VERSION ""

NS_ :

BS_:

BU_: SS EV ACU PT Gateway
VAL_TABLE_ ACS1_DrivingStateMachine 7 "ERROR" 6 "EMERGENCY" 5 "INTERVENTION" 4 "IPC" 3 "REMOTE" 2 "MANUAL" 1 "CHECK" 0 "IDLE" ;
VAL_TABLE_ gear 1 "Request" 0 "No Request" ;

BO_ 3221225472 VECTOR__INDEPENDENT_SIG_MSG: 0 Vector__XXX
 SG_ EPB1_Checksum_Copy_4 : 0|8@1+ (1,0) [0|0] "" Vector__XXX
 SG_ ACS3_Data7 : 0|8@1+ (1,0) [0|255] "" Vector__XXX
 SG_ ACS3_Data6 : 0|8@1+ (1,0) [0|255] "" Vector__XXX
 SG_ ACS3_Data5 : 0|8@1+ (1,0) [0|255] "" Vector__XXX
 SG_ ACS3_Data4 : 0|8@1+ (1,0) [0|255] "" Vector__XXX
 SG_ ACS3_Data3 : 0|8@1+ (1,0) [0|255] "" Vector__XXX
 SG_ ACS3_Data2 : 0|8@1+ (1,0) [0|255] "" Vector__XXX
 SG_ ACS3_Data1 : 0|8@1+ (1,0) [0|255] "" Vector__XXX
 SG_ ACS3_Data0 : 0|8@1+ (1,0) [0|255] "" Vector__XXX
 SG_ DCDC1_Temperature : 0|8@1+ (1,-40) [-40|210] "¡æ" Vector__XXX
 SG_ DCDC1_Status : 0|2@1+ (1,0) [0|3] "" Vector__XXX
 SG_ DCDC1_OutputVoltage : 0|8@1+ (0.1,0) [0|25] "V" Vector__XXX
 SG_ DCDC1_OutputCurrent : 0|10@1+ (1,0) [0|1000] "A" Vector__XXX
 SG_ DCDC1_LiveCounter : 0|4@1+ (1,0) [0|15] "count" Vector__XXX
 SG_ DCDC1_InputVoltage : 0|10@1+ (1,0) [0|1000] "V" Vector__XXX
 SG_ DCDC1_InputCurrent : 0|8@1+ (0.1,0) [0|25] "A" Vector__XXX
 SG_ DCDC1_Checksum : 0|8@1+ (1,0) [0|255] "check" Vector__XXX
 SG_ MCU1_TMTorque : 0|12@1+ (0.25,-500) [-500|500] "Nm" Vector__XXX
 SG_ MCU1_TMTemperature : 0|8@1+ (1,-40) [-40|210] "¡ãC" Vector__XXX
 SG_ MCU1_TMSpeed : 0|16@1+ (1,-30000) [-30000|30000] "rpm" Vector__XXX
 SG_ MCU1_TMCapacitanceVoltage : 0|9@1+ (1,0) [0|500] "V" Vector__XXX
 SG_ MCU1_LiveCounter : 0|4@1+ (1,0) [0|15] "count" Vector__XXX
 SG_ MCU1_Checksum : 0|8@1+ (1,0) [0|255] "check" Vector__XXX
 SG_ ESC1_LiveCounter : 0|4@1+ (1,0) [0|15] "count" Vector__XXX
 SG_ ESC1_Checksum : 0|8@1+ (1,0) [0|255] "check" Vector__XXX
 SG_ ESC1_YawRate : 0|12@1+ (0.05,-100) [-100|100] "deg/s" Vector__XXX
 SG_ ESC1_AccelerationX : 0|12@1+ (0.01,-20) [-20|20] "m/s2" Vector__XXX
 SG_ ESC1_AccelerationY : 0|12@1+ (0.01,-20) [-20|20] "m/s2" Vector__XXX
 SG_ ENV1_LiveCounter : 0|4@1+ (1,0) [0|15] "count" Vector__XXX
 SG_ ENV1_Checksum : 0|8@1+ (1,0) [0|255] "check" Vector__XXX
 SG_ ENV1_TimeYear : 0|6@1+ (1,2000) [2000|2063] "Year" Vector__XXX
 SG_ ENV1_TimeSecond : 0|6@1+ (1,0) [0|59] "Second" Vector__XXX
 SG_ ENV1_TimeMonth : 0|4@1+ (1,1) [1|12] "Month" Vector__XXX
 SG_ ENV1_TimeMinute : 0|6@1+ (1,0) [0|59] "Minute" Vector__XXX
 SG_ ENV1_TimeHour : 0|5@1+ (1,0) [0|23] "Hour" Vector__XXX
 SG_ ENV1_TimeDay : 0|5@1+ (1,1) [1|31] "Day" Vector__XXX
 SG_ ENV1_RainIntensity : 0|4@1+ (10,0) [0|150] "%" Vector__XXX
 SG_ ENV1_BrightnessH : 0|10@1+ (6,0) [0|6138] "LUX" Vector__XXX
 SG_ EPS1_LKAStatus : 0|3@1+ (1,0) [0|7] "" Vector__XXX
 SG_ EPS1_ElectricLoad : 0|8@1+ (0.5,0) [0|120] "A" Vector__XXX
 SG_ EPS1_APAErrorStatus : 0|1@1+ (1,0) [0|1] "" Vector__XXX
 SG_ EPS1_APARequestFeedback : 0|1@1+ (1,0) [0|1] "" Vector__XXX
 SG_ EPS1_APAAbortFeedback : 0|5@1+ (1,0) [0|31] "" Vector__XXX
 SG_ EPS1_OverlayInputTorque : 0|11@1+ (0.01,-10) [-10|10] "Nm" Vector__XXX
 SG_ EPS1_LiveCounter : 0|4@1+ (1,0) [0|15] "count" Vector__XXX
 SG_ EPS1_HandSteeringTorque : 0|11@1+ (0.01,-10) [-10|10] "Nm" Vector__XXX
 SG_ EPS1_Checksum : 0|8@1+ (1,0) [0|255] "check" Vector__XXX
 SG_ BDRR_WinButtonRR_ST : 0|3@1+ (1,0) [0|0] "" Vector__XXX
 SG_ BDRL_WinButtonRL_ST : 0|3@1+ (1,0) [0|0] "" Vector__XXX
 SG_ BDFR_WinButtonFR_ST : 0|3@1+ (1,0) [0|0] "" Vector__XXX
 SG_ A_Test_Data : 0|32@1- (1,0) [0|0] "" Vector__XXX
 SG_ BDFL_MirRightButton_ST : 0|1@1+ (1,0) [0|0] "" Vector__XXX
 SG_ BDFL_MirLeftButton_ST : 0|1@1+ (1,0) [0|0] "" Vector__XXX
 SG_ BDFL_MirButtonUP_ST : 0|1@1+ (1,0) [0|0] "" Vector__XXX
 SG_ BDFL_MirButtonRight_ST : 0|1@1+ (1,0) [0|0] "" Vector__XXX
 SG_ BDFL_MirButtonLeft_ST : 0|1@1+ (1,0) [0|0] "" Vector__XXX
 SG_ BDFL_MirButtonDown_ST : 0|1@1+ (1,0) [0|0] "" Vector__XXX
 SG_ BDFL_UnLockButton_ST : 0|1@1+ (1,0) [0|0] "" Vector__XXX
 SG_ BDFL_LockButton_ST : 0|1@1+ (1,0) [0|0] "" Vector__XXX
 SG_ BDFL_BootButtonFL_ST : 0|1@1+ (1,0) [0|0] "" Vector__XXX
 SG_ BDFL_WinButtonRR_ST : 0|3@1+ (1,0) [0|0] "" Vector__XXX
 SG_ BDFL_WinButtonRL_ST : 0|3@1+ (1,0) [0|0] "" Vector__XXX
 SG_ BDFL_WinButtonFR_ST : 0|3@1+ (1,0) [0|0] "" Vector__XXX
 SG_ BDFL_WinButtonFL_ST : 0|3@1+ (1,0) [0|0] "" Vector__XXX

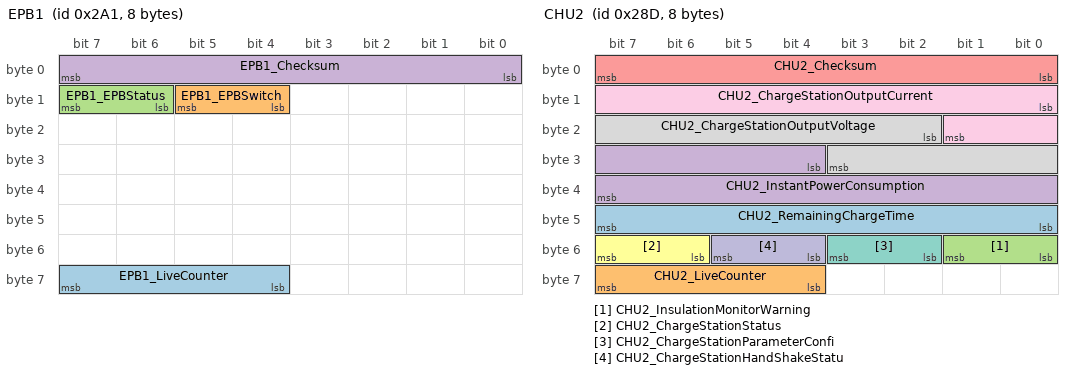
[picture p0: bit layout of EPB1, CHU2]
BO_ 673 EPB1: 8 Vector__XXX
 SG_ EPB1_LiveCounter : 60|4@1+ (1,0) [0|0] "" Vector__XXX
 SG_ EPB1_EPBSwitch : 12|2@1+ (1,0) [0|0] "" Vector__XXX
 SG_ EPB1_EPBStatus : 14|2@1+ (1,0) [0|0] "" Vector__XXX
 SG_ EPB1_Checksum : 0|8@1+ (1,0) [0|0] "" Vector__XXX

BO_ 512 BCM2: 8 Vector__XXX
 SG_ Key_Unlock : 1|1@1+ (1,0) [0|0] "" Vector__XXX
 SG_ Key_Lock : 0|1@1+ (1,0) [0|0] "" Vector__XXX

BO_ 530 VCU3: 8 PT
 SG_ VCU3_ThrottleVoltage : 32|11@1+ (1,0) [0|2000] "mV" Vector__XXX
 SG_ VCU3_MainSwitch : 22|1@1+ (1,0) [0|1] "" Vector__XXX
 SG_ VCU3_IncreaseSpeedSwitch : 26|1@1+ (1,0) [0|1] "" Vector__XXX
 SG_ VCU3_IncreaseDistanceSwitch : 24|1@1+ (1,0) [0|1] "" Vector__XXX
 SG_ VCU3_DecreaseSpeedSwitch : 27|1@1+ (1,0) [0|1] "" Vector__XXX
 SG_ VCU3_DecreaseDistanceSwitch : 25|1@1+ (1,0) [0|1] "" Vector__XXX
 SG_ VCU3_CancelSwitch : 23|1@1+ (1,0) [0|1] "" Vector__XXX
 SG_ VCU3_GearSecurityButton : 20|1@1+ (1,0) [0|1] "" Vector__XXX
 SG_ VCU3_GearParkButton : 21|1@1+ (1,0) [0|1] "" Vector__XXX
 SG_ VCU3_GearLeverPosition : 16|3@1+ (1,0) [0|7] "" Vector__XXX
 SG_ VCU3_EPBSwitch : 28|2@1+ (1,0) [0|3] "" Vector__XXX
 SG_ VCU3_VacuumPressure : 48|10@1+ (0.2,-108) [-108|96.6] "kPa" Vector__XXX
 SG_ VCU3_LiveCounter : 60|4@1+ (1,0) [0|15] "count" Vector__XXX
 SG_ VCU3_LeverInfo : 8|4@1+ (1,0) [0|15] "" Vector__XXX
 SG_ VCU3_EPBStatus : 30|2@1+ (1,0) [0|3] "" Vector__XXX
 SG_ VCU3_Checksum : 0|8@1+ (1,0) [0|255] "check" Vector__XXX
 SG_ VCU3_ActualGear : 12|4@1+ (1,0) [0|15] "" Vector__XXX

BO_ 653 CHU2: 8 EV
 SG_ CHU2_RemainingChargeTime : 40|8@1+ (5,0) [0|1000] "Min" Vector__XXX
 SG_ CHU2_LiveCounter : 60|4@1+ (1,0) [0|15] "count" Vector__XXX
 SG_ CHU2_InsulationMonitorWarning : 48|2@1+ (1,0) [0|3] "" Vector__XXX
 SG_ CHU2_InstantPowerConsumption : 28|12@1+ (0.5,-500) [-500|1500] "Kw" Vector__XXX
 SG_ CHU2_Checksum : 0|8@1+ (1,0) [0|255] "check" Vector__XXX
 SG_ CHU2_ChargeStationStatus : 54|2@1+ (1,0) [0|3] "" Vector__XXX
 SG_ CHU2_ChargeStationParameterConfi : 50|2@1+ (1,0) [0|3] "" Vector__XXX
 SG_ CHU2_ChargeStationOutputVoltage : 18|10@1+ (1,0) [0|1000] "V" Vector__XXX
 SG_ CHU2_ChargeStationOutputCurrent : 8|10@1+ (1,0) [0|1000] "A" Vector__XXX
 SG_ CHU2_ChargeStationHandShakeStatu : 52|2@1+ (1,0) [0|3] "" Vector__XXX

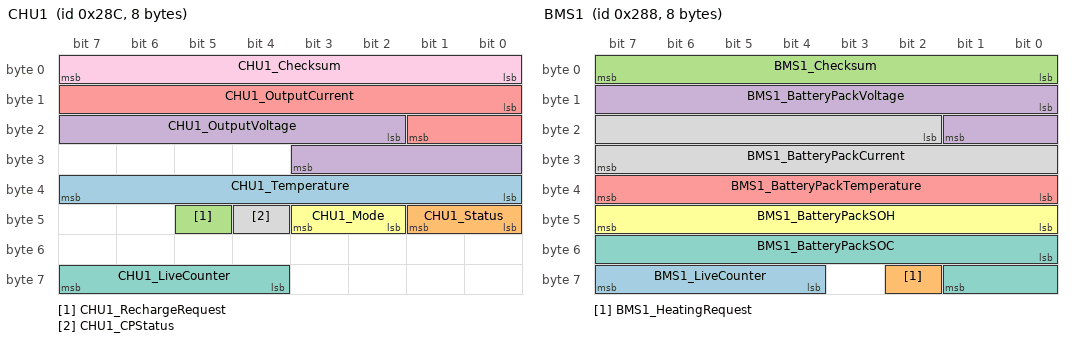
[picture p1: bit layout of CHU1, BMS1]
BO_ 652 CHU1: 8 EV
 SG_ CHU1_Temperature : 32|8@1+ (1,-40) [-40|210] "¡æ" Vector__XXX
 SG_ CHU1_Status : 40|2@1+ (1,0) [0|3] "" Vector__XXX
 SG_ CHU1_RechargeRequest : 45|1@1+ (1,0) [0|1] "" Vector__XXX
 SG_ CHU1_OutputVoltage : 18|10@1+ (1,0) [0|1000] "V" Vector__XXX
 SG_ CHU1_OutputCurrent : 8|10@1+ (0.1,0) [0|100] "A" Vector__XXX
 SG_ CHU1_Mode : 42|2@1+ (1,0) [0|3] "" Vector__XXX
 SG_ CHU1_LiveCounter : 60|4@1+ (1,0) [0|15] "count" Vector__XXX
 SG_ CHU1_CPStatus : 44|1@1+ (1,0) [0|1] "" Vector__XXX
 SG_ CHU1_Checksum : 0|8@1+ (1,0) [0|255] "check" Vector__XXX

BO_ 648 BMS1: 8 EV
 SG_ BMS1_LiveCounter : 60|4@1+ (1,0) [0|15] "count" Vector__XXX
 SG_ BMS1_HeatingRequest : 58|1@1+ (1,0) [0|1] "" Vector__XXX
 SG_ BMS1_Checksum : 0|8@1+ (1,0) [0|255] "check" Vector__XXX
 SG_ BMS1_BatteryPackVoltage : 8|10@1+ (1,0) [0|1000] "V" Vector__XXX
 SG_ BMS1_BatteryPackTemperature : 32|8@1+ (1,-40) [-40|210] "¡æ" Vector__XXX
 SG_ BMS1_BatteryPackSOH : 40|8@1+ (1,0) [0|100] "%" Vector__XXX
 SG_ BMS1_BatteryPackSOC : 48|10@1+ (0.1,0) [0|100] "%" Vector__XXX
 SG_ BMS1_BatteryPackCurrent : 18|14@1+ (0.1,-800) [-800|800] "A" Vector__XXX

BO_ 340 ACU4: 8 ACU
 SG_ ACU4_PowerRequest : 32|2@1+ (1,0) [0|3] "" Vector__XXX
 SG_ ACU4_RRWindow_Request : 30|2@1+ (1,0) [0|0] "" Vector__XXX
 SG_ ACU4_RLWindow_Request : 28|2@1+ (1,0) [0|0] "" Vector__XXX
 SG_ ACU4_Lock_Request : 16|2@1+ (1,0) [0|0] "" Vector__XXX
 SG_ ACU4_FRWindow_Request : 26|2@1+ (1,0) [0|0] "" Vector__XXX
 SG_ ACU4_FLWindow_Request : 24|2@1+ (1,0) [0|0] "" Vector__XXX
 SG_ ACU4_Boot_Request : 18|2@1+ (1,0) [0|0] "" Vector__XXX
 SG_ ACU4_RearWiperRequest : 22|2@1+ (1,0) [0|3] "" Vector__XXX
 SG_ ACU4_LED4Request : 59|1@1+ (1,0) [0|1] "" Vector__XXX
 SG_ ACU4_LED3Request : 58|1@1+ (1,0) [0|1] "" Vector__XXX
 SG_ ACU4_LED2Request : 57|1@1+ (1,0) [0|1] "" Vector__XXX
 SG_ ACU4_LED1Request : 56|1@1+ (1,0) [0|1] "" Vector__XXX
 SG_ ACU4_LampHorn : 11|1@1+ (1,0) [0|1] "" Vector__XXX
 SG_ ACU4_WhistleRequest : 14|2@1+ (1,0) [0|3] "" Vector__XXX
 SG_ ACU4_FrontWiperRequest : 20|2@1+ (1,0) [0|3] "" Vector__XXX
 SG_ ACU4_BeamLampRequest : 12|2@1+ (1,0) [0|3] "" Vector__XXX
 SG_ ACU4_LiveCounter : 60|4@1+ (1,0) [0|15] "count" Vector__XXX
 SG_ ACU4_Checksum : 0|8@1+ (1,0) [0|255] "check" Vector__XXX
 SG_ ACU4_SteeringLampRequest : 8|2@1+ (1,0) [0|3] "" Vector__XXX
 SG_ ACU4_HazardLampRequest : 10|1@1+ (1,0) [0|1] "" Vector__XXX

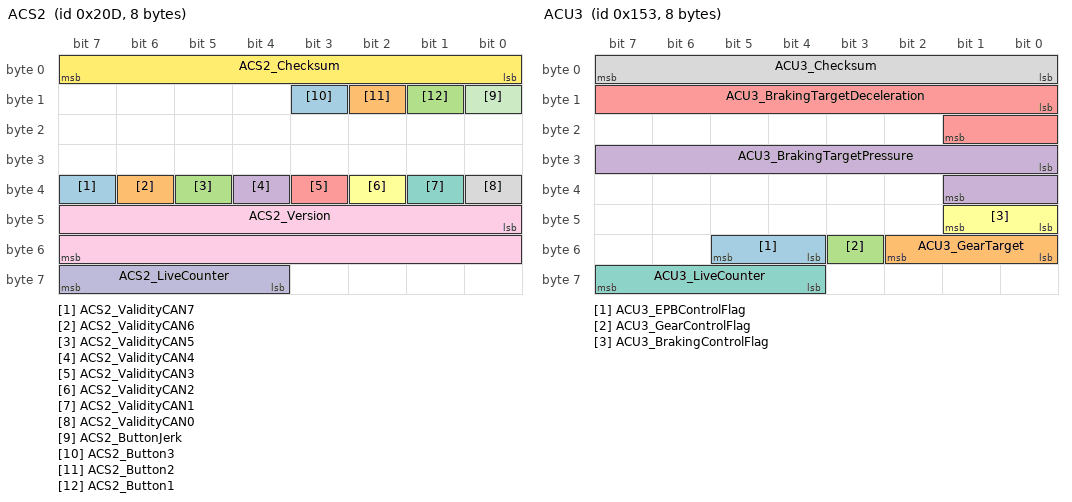
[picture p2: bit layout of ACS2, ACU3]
BO_ 525 ACS2: 8 PT
 SG_ ACS2_ValidityCAN7 : 39|1@1+ (1,0) [0|1] "" Vector__XXX
 SG_ ACS2_ValidityCAN6 : 38|1@1+ (1,0) [0|1] "" Vector__XXX
 SG_ ACS2_ValidityCAN5 : 37|1@1+ (1,0) [0|1] "" Vector__XXX
 SG_ ACS2_ValidityCAN4 : 36|1@1+ (1,0) [0|1] "" Vector__XXX
 SG_ ACS2_ValidityCAN3 : 35|1@1+ (1,0) [0|1] "" Vector__XXX
 SG_ ACS2_ValidityCAN2 : 34|1@1+ (1,0) [0|1] "" Vector__XXX
 SG_ ACS2_ValidityCAN1 : 33|1@1+ (1,0) [0|1] "" Vector__XXX
 SG_ ACS2_ValidityCAN0 : 32|1@1+ (1,0) [0|1] "" Vector__XXX
 SG_ ACS2_Version : 40|16@1+ (0.01,0) [0|655.35] "version" Vector__XXX
 SG_ ACS2_LiveCounter : 60|4@1+ (1,0) [0|15] "count" Vector__XXX
 SG_ ACS2_ButtonJerk : 8|1@1+ (1,0) [0|1] "" Vector__XXX
 SG_ ACS2_Checksum : 0|8@1+ (1,0) [0|255] "check" Vector__XXX
 SG_ ACS2_Button3 : 11|1@1+ (1,0) [0|1] "" Vector__XXX
 SG_ ACS2_Button2 : 10|1@1+ (1,0) [0|1] "" Vector__XXX
 SG_ ACS2_Button1 : 9|1@1+ (1,0) [0|1] "" Vector__XXX

BO_ 339 ACU3: 8 ACU
 SG_ ACU3_EPBControlFlag : 52|2@1+ (1,0) [0|3] "" Vector__XXX
 SG_ ACU3_GearTarget : 48|3@1+ (1,0) [0|7] "" Vector__XXX
 SG_ ACU3_GearControlFlag : 51|1@1+ (1,0) [0|1] "" Vector__XXX
 SG_ ACU3_BrakingTargetPressure : 24|10@1+ (0.01,0) [0|10] "Mpa" Vector__XXX
 SG_ ACU3_BrakingTargetDeceleration : 8|10@1+ (-0.01,0) [-10|0] "m/s2" Vector__XXX
 SG_ ACU3_BrakingControlFlag : 40|2@1+ (1,0) [0|3] "" Vector__XXX
 SG_ ACU3_LiveCounter : 60|4@1+ (1,0) [0|15] "count" Vector__XXX
 SG_ ACU3_Checksum : 0|8@1+ (1,0) [0|255] "check" Vector__XXX

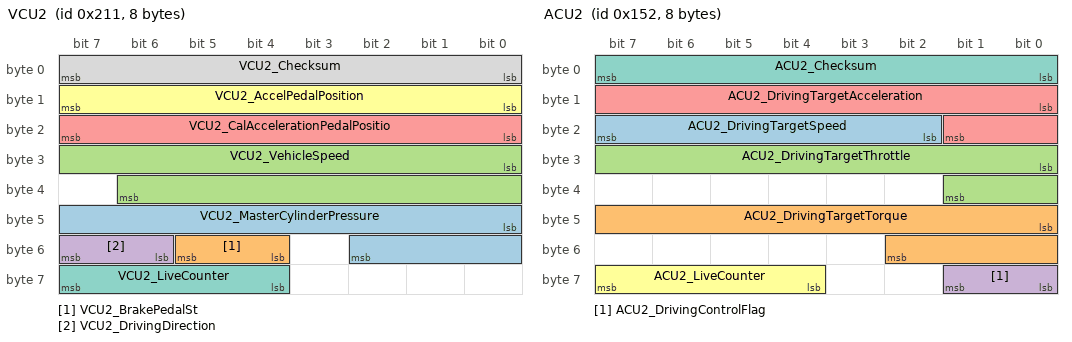
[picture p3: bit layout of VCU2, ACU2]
BO_ 529 VCU2: 8 PT
 SG_ VCU2_MasterCylinderPressure : 40|11@1+ (0.1,0) [0|200] "bar" Vector__XXX
 SG_ VCU2_BrakePedalSt : 52|2@1+ (1,0) [0|3] "" Vector__XXX
 SG_ VCU2_VehicleSpeed : 24|15@1+ (0.01,0) [0|300] "km/h" Vector__XXX
 SG_ VCU2_DrivingDirection : 54|2@1+ (1,0) [0|3] "" Vector__XXX
 SG_ VCU2_CalAccelerationPedalPositio : 16|8@1+ (0.4,0) [0|100] "%" Vector__XXX
 SG_ VCU2_AccelPedalPosition : 8|8@1+ (0.4,0) [0|100] "%" Vector__XXX
 SG_ VCU2_LiveCounter : 60|4@1+ (1,0) [0|15] "count" Vector__XXX
 SG_ VCU2_Checksum : 0|8@1+ (1,0) [0|255] "check" Vector__XXX

BO_ 338 ACU2: 8 ACU
 SG_ ACU2_DrivingTargetSpeed : 18|6@1+ (2,0) [0|126] "km/h" Vector__XXX
 SG_ ACU2_DrivingTargetTorque : 40|11@1+ (0.25,0) [0|350] "Nm" Vector__XXX
 SG_ ACU2_DrivingTargetThrottle : 24|10@1+ (0.1,0) [0|100] "%" Vector__XXX
 SG_ ACU2_DrivingControlFlag : 56|2@1+ (1,0) [0|3] "" Vector__XXX
 SG_ ACU2_DrivingTargetAcceleration : 8|10@1+ (0.01,0) [0|10] "m/s2" Vector__XXX
 SG_ ACU2_LiveCounter : 60|4@1+ (1,0) [0|15] "count" Vector__XXX
 SG_ ACU2_Checksum : 0|8@1+ (1,0) [0|255] "check" Vector__XXX

BO_ 524 ACS1: 8 PT
 SG_ ACS1_WorkMode : 48|2@1+ (1,0) [0|3] "" Vector__XXX
 SG_ ACS1_SteeringStateMachine : 12|4@1+ (1,0) [0|15] "value" Vector__XXX
 SG_ ACS1_GearStateMachine : 36|4@1+ (1,0) [0|15] "value" Vector__XXX
 SG_ ACS1_DrivingStateMachine : 20|4@1+ (1,0) [0|15] "value" Vector__XXX
 SG_ ACS1_BrakingStateMachine : 28|4@1+ (1,0) [0|15] "value" Vector__XXX
 SG_ ACS1_GearTakeOverSt : 34|2@1+ (1,0) [0|3] "" Vector__XXX
 SG_ ACS1_GearFailureSt : 46|2@1+ (1,0) [0|3] "" Vector__XXX
 SG_ ACS1_GearAutoControlSt : 32|2@1+ (1,0) [0|3] "" Vector__XXX
 SG_ ACS1_SteeringTakeOverSt : 10|2@1+ (1,0) [0|3] "" Vector__XXX
 SG_ ACS1_SteeringFailureSt : 40|2@1+ (1,0) [0|3] "" Vector__XXX
 SG_ ACS1_SteeringAutoControlSt : 8|2@1+ (1,0) [0|3] "" Vector__XXX
 SG_ ACS1_LiveCounter : 60|4@1+ (1,0) [0|15] "count" Vector__XXX
 SG_ ACS1_DrivingTakeOverSt : 18|2@1+ (1,0) [0|3] "" Vector__XXX
 SG_ ACS1_DrivingFailureSt : 42|2@1+ (1,0) [0|3] "" Vector__XXX
 SG_ ACS1_DrivingAutoControlSt : 16|2@1+ (1,0) [0|3] "" Vector__XXX
 SG_ ACS1_Checksum : 0|8@1+ (1,0) [0|255] "check" Vector__XXX
 SG_ ACS1_BrakingTakeOverSt : 26|2@1+ (1,0) [0|3] "" Vector__XXX
 SG_ ACS1_BrakingFailureSt : 44|2@1+ (1,0) [0|3] "" Vector__XXX
 SG_ ACS1_BrakingAutoControlSt : 24|2@1+ (1,0) [0|3] "" Vector__XXX

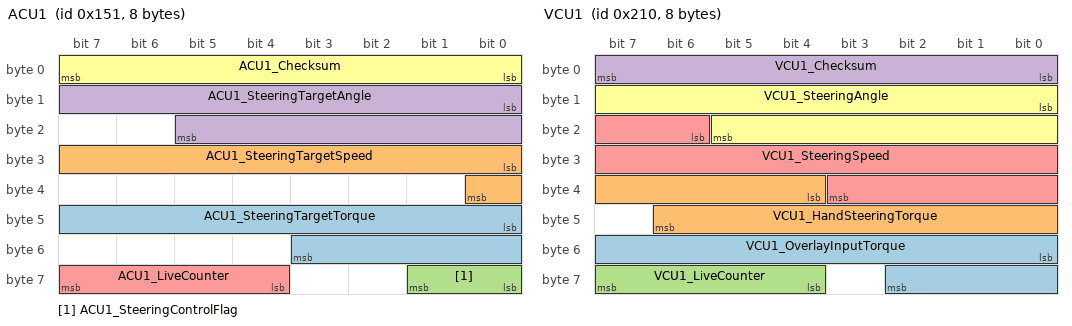
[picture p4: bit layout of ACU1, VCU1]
BO_ 337 ACU1: 8 ACU
 SG_ ACU1_SteeringTargetTorque : 40|12@1+ (0.01,-20) [-20|20] "Nm" Vector__XXX
 SG_ ACU1_SteeringTargetSpeed : 24|9@1+ (1,0) [0|500] "deg/s" Vector__XXX
 SG_ ACU1_SteeringControlFlag : 56|2@1+ (1,0) [0|3] "" Vector__XXX
 SG_ ACU1_SteeringTargetAngle : 8|14@1+ (0.1,-600) [-600|600] "deg" Vector__XXX
 SG_ ACU1_LiveCounter : 60|4@1+ (1,0) [0|15] "count" Vector__XXX
 SG_ ACU1_Checksum : 0|8@1+ (1,0) [0|255] "check" Vector__XXX

BO_ 528 VCU1: 8 PT
 SG_ VCU1_OverlayInputTorque : 48|11@1+ (0.01,-10) [-10|10] "Nm" Vector__XXX
 SG_ VCU1_HandSteeringTorque : 36|11@1+ (0.01,-10) [-10|10] "Nm" Vector__XXX
 SG_ VCU1_LiveCounter : 60|4@1+ (1,0) [0|15] "count" Vector__XXX
 SG_ VCU1_Checksum : 0|8@1+ (1,0) [0|255] "check" Vector__XXX
 SG_ VCU1_SteeringSpeed : 22|14@1+ (0.1,-600) [-600|600] "deg/s" Vector__XXX
 SG_ VCU1_SteeringAngle : 8|14@1+ (0.1,-600) [-600|600] "deg" Vector__XXX

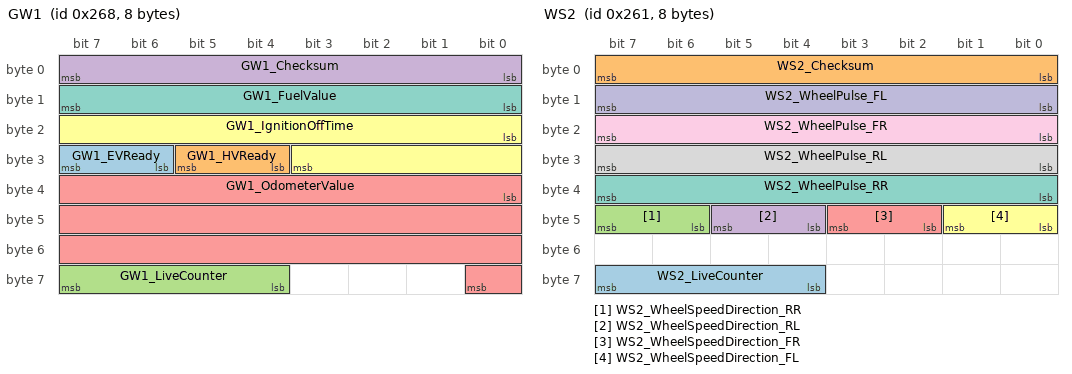
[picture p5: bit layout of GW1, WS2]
BO_ 616 GW1: 8 PT
 SG_ GW1_EVReady : 30|2@1+ (1,0) [0|3] "" Vector__XXX
 SG_ GW1_HVReady : 28|2@1+ (1,0) [0|3] "" Vector__XXX
 SG_ GW1_LiveCounter : 60|4@1+ (1,0) [0|15] "count" Vector__XXX
 SG_ GW1_Checksum : 0|8@1+ (1,0) [0|255] "check" Vector__XXX
 SG_ GW1_OdometerValue : 32|25@1+ (0.1,0) [0|3355443] "km" Vector__XXX
 SG_ GW1_IgnitionOffTime : 16|12@1+ (1,0) [0|4093] "minute" Vector__XXX
 SG_ GW1_FuelValue : 8|8@1+ (1,0) [0|254] "L" Vector__XXX

BO_ 609 WS2: 8 PT
 SG_ WS2_LiveCounter : 60|4@1+ (1,0) [0|15] "count" Vector__XXX
 SG_ WS2_Checksum : 0|8@1+ (1,0) [0|255] "check" Vector__XXX
 SG_ WS2_WheelSpeedDirection_RR : 46|2@1+ (1,0) [0|3] "" Vector__XXX
 SG_ WS2_WheelSpeedDirection_RL : 44|2@1+ (1,0) [0|3] "" Vector__XXX
 SG_ WS2_WheelSpeedDirection_FR : 42|2@1+ (1,0) [0|3] "" Vector__XXX
 SG_ WS2_WheelSpeedDirection_FL : 40|2@1+ (1,0) [0|3] "" Vector__XXX
 SG_ WS2_WheelPulse_RR : 32|8@1+ (1,0) [0|254] "pulse" Vector__XXX
 SG_ WS2_WheelPulse_RL : 24|8@1+ (1,0) [0|254] "pulse" Vector__XXX
 SG_ WS2_WheelPulse_FR : 16|8@1+ (1,0) [0|254] "pulse" Vector__XXX
 SG_ WS2_WheelPulse_FL : 8|8@1+ (1,0) [0|254] "pulse" Vector__XXX

BO_ 672 BCM1: 8 PT
 SG_ BCM1_PassengerSideBuckle : 54|2@1+ (1,0) [0|3] "" Vector__XXX
 SG_ BCM1_WiperSpeed : 37|3@1+ (1,0) [0|7] "" Vector__XXX
 SG_ BCM1_PositionLightSt : 32|2@1+ (1,0) [0|3] "" Vector__XXX
 SG_ BCM1_MirrorFoldSt_FR : 50|2@1+ (1,0) [0|3] "" Vector__XXX
 SG_ BCM1_MirrorFoldSt_FL : 48|2@1+ (1,0) [0|3] "" Vector__XXX
 SG_ BCM1_DriverSideBuckle : 52|2@1+ (1,0) [0|3] "" Vector__XXX
 SG_ BCM1_WiperStatus : 34|3@1+ (1,0) [0|7] "" Vector__XXX
 SG_ BCM1_LuggageDoorSt : 21|1@1+ (1,0) [0|1] "" Vector__XXX
 SG_ BCM1_LowBeamSt : 28|2@1+ (1,0) [0|3] "" Vector__XXX
 SG_ BCM1_HighBeamSt : 30|2@1+ (1,0) [0|3] "" Vector__XXX
 SG_ BCM1_EngHoodSt : 20|1@1+ (1,0) [0|1] "" Vector__XXX
 SG_ BCM1_RRDoorLockSt : 14|2@1+ (1,0) [0|3] "" Vector__XXX
 SG_ BCM1_RRDoorSt : 19|1@1+ (1,0) [0|1] "" Vector__XXX
 SG_ BCM1_RLDoorLockSt : 12|2@1+ (1,0) [0|3] "" Vector__XXX
 SG_ BCM1_RLDoorSt : 18|1@1+ (1,0) [0|1] "" Vector__XXX
 SG_ BCM1_PassengerDoorLockSt : 10|2@1+ (1,0) [0|3] "" Vector__XXX
 SG_ BCM1_PassengerDoorSt : 17|1@1+ (1,0) [0|1] "" Vector__XXX
 SG_ BCM1_DriverDoorLockSt : 8|2@1+ (1,0) [0|3] "" Vector__XXX
 SG_ BCM1_DriverDoorSt : 16|1@1+ (1,0) [0|1] "" Vector__XXX
 SG_ BCM1_LiveCounter : 60|4@1+ (1,0) [0|15] "count" Vector__XXX
 SG_ BCM1_Checksum : 0|8@1+ (1,0) [0|255] "check" Vector__XXX
 SG_ BCM1_SteeringLightSt : 24|2@1+ (1,0) [0|3] "" Vector__XXX
 SG_ BCM1_HazardLightSt : 26|2@1+ (1,0) [0|3] "" Vector__XXX

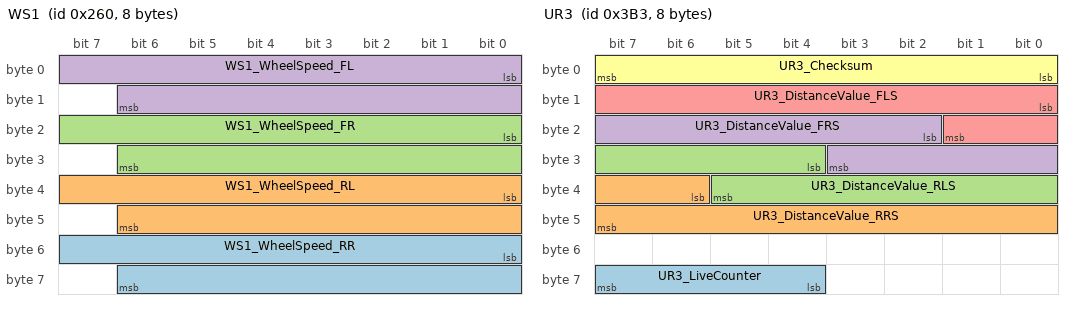
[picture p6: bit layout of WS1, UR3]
BO_ 608 WS1: 8 PT
 SG_ WS1_WheelSpeed_RR : 48|15@1+ (0.01,0) [0|300] "km/h" Vector__XXX
 SG_ WS1_WheelSpeed_RL : 32|15@1+ (0.01,0) [0|300] "km/h" Vector__XXX
 SG_ WS1_WheelSpeed_FR : 16|15@1+ (0.01,0) [0|300] "km/h" Vector__XXX
 SG_ WS1_WheelSpeed_FL : 0|15@1+ (0.01,0) [0|300] "km/h" Vector__XXX

BO_ 947 UR3: 8 SS
 SG_ UR3_LiveCounter : 60|4@1+ (1,0) [0|15] "count" Vector__XXX
 SG_ UR3_DistanceValue_RRS : 38|10@1+ (1,0) [0|1023] "cm" Vector__XXX
 SG_ UR3_DistanceValue_RLS : 28|10@1+ (1,0) [0|1023] "cm" Vector__XXX
 SG_ UR3_DistanceValue_FRS : 18|10@1+ (1,0) [0|1023] "cm" Vector__XXX
 SG_ UR3_DistanceValue_FLS : 8|10@1+ (1,0) [0|1023] "cm" Vector__XXX
 SG_ UR3_Checksum : 0|8@1+ (1,0) [0|255] "check" Vector__XXX

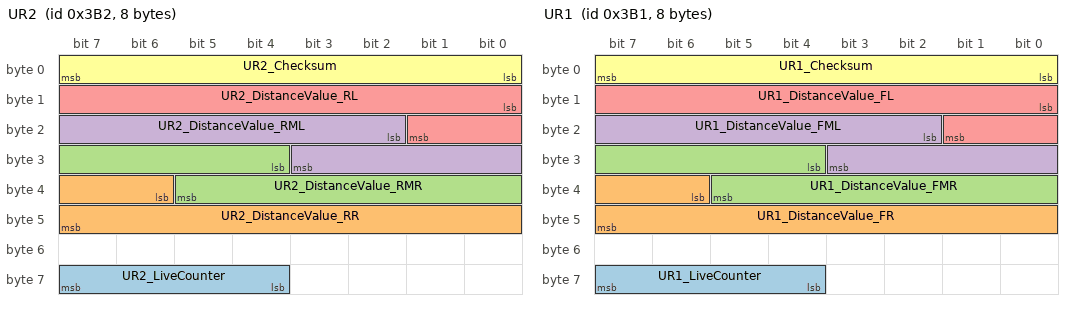
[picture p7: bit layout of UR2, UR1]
BO_ 946 UR2: 8 SS
 SG_ UR2_LiveCounter : 60|4@1+ (1,0) [0|15] "count" Vector__XXX
 SG_ UR2_DistanceValue_RR : 38|10@1+ (1,0) [0|1023] "cm" Vector__XXX
 SG_ UR2_DistanceValue_RMR : 28|10@1+ (1,0) [0|1023] "cm" Vector__XXX
 SG_ UR2_DistanceValue_RML : 18|10@1+ (1,0) [0|1023] "cm" Vector__XXX
 SG_ UR2_DistanceValue_RL : 8|10@1+ (1,0) [0|1023] "cm" Vector__XXX
 SG_ UR2_Checksum : 0|8@1+ (1,0) [0|255] "check" Vector__XXX

BO_ 945 UR1: 8 SS
 SG_ UR1_LiveCounter : 60|4@1+ (1,0) [0|15] "count" Vector__XXX
 SG_ UR1_DistanceValue_FR : 38|10@1+ (1,0) [0|1023] "cm" Vector__XXX
 SG_ UR1_DistanceValue_FMR : 28|10@1+ (1,0) [0|1023] "cm" Vector__XXX
 SG_ UR1_DistanceValue_FML : 18|10@1+ (1,0) [0|1023] "cm" Vector__XXX
 SG_ UR1_DistanceValue_FL : 8|10@1+ (1,0) [0|1023] "cm" Vector__XXX
 SG_ UR1_Checksum : 0|8@1+ (1,0) [0|255] "check" Vector__XXX

CM_ BO_ 3221225472 "This is a message for not used signals, created by Vector CANdb++ DBC OLE DB Provider.";
CM_ SG_ 3221225472 DCDC1_LiveCounter "The Livecounter is used to check the signal consistency of the messages";
CM_ SG_ 3221225472 DCDC1_Checksum "The checksum is used to check whether the data transmission errors";
CM_ SG_ 3221225472 MCU1_LiveCounter "The Livecounter is used to check the signal consistency of the messages";
CM_ SG_ 3221225472 MCU1_Checksum "The checksum is used to check whether the data transmission errors";
CM_ SG_ 3221225472 ESC1_LiveCounter "The Livecounter is used to check the signal consistency of the messages";
CM_ SG_ 3221225472 ESC1_Checksum "The checksum is used to check whether the data transmission errors";
CM_ SG_ 3221225472 ESC1_YawRate "This signal indicates the yaw rate data (real data; sign depends on mounting position).anticlockwise=positive, clockwise=negative";
CM_ SG_ 3221225472 ESC1_AccelerationX "The signal is LongitudinalAcceleration(exact value).Positive value represents  forward,  negative value represents backward.";
CM_ SG_ 3221225472 ESC1_AccelerationY "The signal is Lateral Acceleration(exact value).Positive value represents right side of vehicle, negative value represents  left side of vehicle.";
CM_ SG_ 3221225472 ENV1_LiveCounter "The Livecounter is used to check the signal consistency of the messages";
CM_ SG_ 3221225472 ENV1_Checksum "The checksum is used to check whether the data transmission errors";
CM_ SG_ 3221225472 ENV1_TimeYear "Indicates the GPS year";
CM_ SG_ 3221225472 ENV1_TimeSecond "Indicates the GPS second ";
CM_ SG_ 3221225472 ENV1_TimeMonth "Indicates the GPS month";
CM_ SG_ 3221225472 ENV1_TimeMinute "Indicates the GPS minute  ";
CM_ SG_ 3221225472 ENV1_TimeHour "Indicates the GPS hour";
CM_ SG_ 3221225472 ENV1_TimeDay "Indicates the GPS day";
CM_ SG_ 3221225472 ENV1_RainIntensity "This signal delivers information about rain intensity: from 0% (no rain) to 100% (very heavy rain).";
CM_ SG_ 3221225472 ENV1_BrightnessH "This signal  indicate the high precision light intensity expressed in 10 Bit.";
CM_ SG_ 3221225472 EPS1_LKAStatus "The signal indicates the status of LKA function";
CM_ SG_ 3221225472 EPS1_ElectricLoad "The signal indicates the load of the electric steering motor. If the load could not be measured or an error is detected on the motor, the invalid value of the signal is set";
CM_ SG_ 3221225472 EPS1_APAErrorStatus "The signal indicates the status of APA function error";
CM_ SG_ 3221225472 EPS1_APARequestFeedback "EPS APA Request Feedback";
CM_ SG_ 3221225472 EPS1_APAAbortFeedback "EPS APA Abort Feedback";
CM_ SG_ 3221225472 EPS1_OverlayInputTorque "The signal indicates the actual applied overlay toque in EPS.";
CM_ SG_ 3221225472 EPS1_LiveCounter "The Livecounter is used to check the signal consistency of the messages";
CM_ SG_ 3221225472 EPS1_HandSteeringTorque "The signal indicates the torque measured by the torque sensor at the steering wheel";
CM_ SG_ 3221225472 EPS1_Checksum "The checksum is used to check whether the data transmission errors";
CM_ SG_ 3221225472 BDRR_WinButtonRR_ST "1 down2 £» 2 down1£»3ÖÐ¼ä  £»4 up1   £»5up2";
CM_ SG_ 3221225472 BDRL_WinButtonRL_ST "1 down2 £» 2 down1£»3ÖÐ¼ä  £»4 up1   £»5up2";
CM_ SG_ 3221225472 BDFR_WinButtonFR_ST "1 down2 £» 2 down1£»3ÖÐ¼ä  £»4 up1   £»5up2";
CM_ SG_ 3221225472 BDFL_MirRightButton_ST "ºóÊÓ¾µÑ¡ÔñÓÒ°´¼ü£º1 °´ÏÂ £»0Ã»ÓÐ°´ÏÂ";
CM_ SG_ 3221225472 BDFL_MirLeftButton_ST "ºóÊÓ¾µÑ¡Ôñ×ó°´¼ü£º1 °´ÏÂ £»0Ã»ÓÐ°´ÏÂ";
CM_ SG_ 3221225472 BDFL_MirButtonUP_ST "ºóÊÓ¾µÏòÉÏµ÷Õû°´¼ü  1 °´ÏÂ£»0 Ã»ÓÐ°´ÏÂ
";
CM_ SG_ 3221225472 BDFL_MirButtonRight_ST "ºóÊÓ¾µÏòÓÒµ÷Õû°´¼ü  1 °´ÏÂ£»0 Ã»ÓÐ°´ÏÂ";
CM_ SG_ 3221225472 BDFL_MirButtonLeft_ST "ºóÊÓ¾µÏò×óµ÷Õû°´¼ü  1 °´ÏÂ£»0 Ã»ÓÐ°´ÏÂ";
CM_ SG_ 3221225472 BDFL_MirButtonDown_ST "ºóÊÓ¾µÏòÏÂµ÷Õû°´¼ü  1 °´ÏÂ£»0 Ã»ÓÐ°´ÏÂ";
CM_ SG_ 3221225472 BDFL_UnLockButton_ST "1,°´ÏÂ £»0£¬Ã»ÓÐ°´ÏÂ";
CM_ SG_ 3221225472 BDFL_LockButton_ST "1,°´ÏÂ £»0£¬Ã»ÓÐ°´ÏÂ";
CM_ SG_ 3221225472 BDFL_BootButtonFL_ST "1,°´ÏÂ 0£¬Ã»ÓÐ°´ÏÂ";
CM_ SG_ 3221225472 BDFL_WinButtonRR_ST "1 down2 £» 2 down1£»3ÖÐ¼ä  £»4 up1   £»5up2";
CM_ SG_ 3221225472 BDFL_WinButtonRL_ST "1 down2 £» 2 down1£»3ÖÐ¼ä  £»4 up1   £»5up2";
CM_ SG_ 3221225472 BDFL_WinButtonFR_ST "1 down2 £» 2 down1£»3ÖÐ¼ä  £»4 up1   £»5up2";
CM_ SG_ 3221225472 BDFL_WinButtonFL_ST "1 down2 £» 2 down1£»3ÖÐ¼ä  £»4 up1   £»5up2";
CM_ SG_ 673 EPB1_LiveCounter "The Livecounter is used to check the signal consistency of the messages";
CM_ SG_ 673 EPB1_EPBSwitch "0:no request 1: lock 2 :release 3: reserved";
CM_ SG_ 673 EPB1_EPBStatus "0: released 1: locked 2: releasing 3:locking";
CM_ SG_ 530 VCU3_MainSwitch "The signal indicates if the  ON/OFF cruise control switch is actived or not.";
CM_ SG_ 530 VCU3_IncreaseSpeedSwitch "The signal indicates if the increase speed switch is actived or not";
CM_ SG_ 530 VCU3_IncreaseDistanceSwitch "The signal indicates if  increase distance switch is actived or not";
CM_ SG_ 530 VCU3_DecreaseSpeedSwitch "The signal indicates if the decrease speed switch is actived or not.";
CM_ SG_ 530 VCU3_DecreaseDistanceSwitch "The signal indicates if decrease distance switch is actived or not";
CM_ SG_ 530 VCU3_CancelSwitch "The signal indicates if the cancel cruise control switch is actived or not";
CM_ SG_ 530 VCU3_GearSecurityButton "This signal indicate the security button in the knob is pressed or not.";
CM_ SG_ 530 VCU3_GearParkButton "This signal indicate the park button in the knob is pressed or not.";
CM_ SG_ 530 VCU3_GearLeverPosition "This signal indicate the current lever position.";
CM_ SG_ 530 VCU3_EPBSwitch "This signal indicate the EPB switch status.";
CM_ SG_ 530 VCU3_LiveCounter "The Livecounter is used to check the signal consistency of the messages";
CM_ SG_ 530 VCU3_LeverInfo "This signal indicates the lever position information which should be displayed on the dashboard. For H72G, only P,R,N,D,M,no connection.";
CM_ SG_ 530 VCU3_EPBStatus "The signal indicates the working status of EPB.";
CM_ SG_ 530 VCU3_Checksum "The checksum is used to check whether the data transmission errors";
CM_ SG_ 530 VCU3_ActualGear "The signal indicates to the actual gear status, it shows in which gear the transmission system is in at the moment (engaged gear).";
CM_ SG_ 653 CHU2_LiveCounter "The Livecounter is used to check the signal consistency of the messages";
CM_ SG_ 653 CHU2_Checksum "The checksum is used to check whether the data transmission errors";
CM_ SG_ 652 CHU1_LiveCounter "The Livecounter is used to check the signal consistency of the messages";
CM_ SG_ 652 CHU1_Checksum "The checksum is used to check whether the data transmission errors";
CM_ SG_ 648 BMS1_LiveCounter "The Livecounter is used to check the signal consistency of the messages";
CM_ SG_ 648 BMS1_Checksum "The checksum is used to check whether the data transmission errors";
CM_ SG_ 340 ACU4_PowerRequest "1: KL15 ON  3KL15 OFF";
CM_ SG_ 340 ACU4_RRWindow_Request "1:fall  2:rise 3:stop";
CM_ SG_ 340 ACU4_RLWindow_Request "1:fall  2:rise 3:stop";
CM_ SG_ 340 ACU4_Lock_Request "1:lock  2:unlock
";
CM_ SG_ 340 ACU4_FRWindow_Request "1:fall  2:rise 3:stop";
CM_ SG_ 340 ACU4_FLWindow_Request "1:fall  2:rise 3:stop";
CM_ SG_ 340 ACU4_Boot_Request "1:on  2:off 3:stop";
CM_ SG_ 340 ACU4_LampHorn "This signal is the the horn lamp or request";
CM_ SG_ 340 ACU4_WhistleRequest "0 stop 1 horn";
CM_ SG_ 340 ACU4_FrontWiperRequest "0 stop 1:inject water 2slow 3fast";
CM_ SG_ 340 ACU4_BeamLampRequest "0:OFF 1:LOW 2£ºHIGH";
CM_ SG_ 340 ACU4_LiveCounter "The Livecounter is used to check the signal consistency of the messages";
CM_ SG_ 340 ACU4_Checksum "The checksum is used to check whether the data transmission errors";
CM_ SG_ 340 ACU4_SteeringLampRequest "This signal is steering light request";
CM_ SG_ 340 ACU4_HazardLampRequest "This signal is hazard light request";
CM_ SG_ 525 ACS2_ValidityCAN7 "This signal indicates the validity of CAN5";
CM_ SG_ 525 ACS2_ValidityCAN6 "This signal indicates the validity of CAN4";
CM_ SG_ 525 ACS2_ValidityCAN5 "This signal indicates the validity of CAN5";
CM_ SG_ 525 ACS2_ValidityCAN4 "This signal indicates the validity of CAN4";
CM_ SG_ 525 ACS2_ValidityCAN3 "This signal indicates the validity of CAN3";
CM_ SG_ 525 ACS2_ValidityCAN2 "This signal indicates the validity of CAN2";
CM_ SG_ 525 ACS2_ValidityCAN1 "This signal indicates the validity of CAN1";
CM_ SG_ 525 ACS2_ValidityCAN0 "This signal indicates the validity of CAN0";
CM_ SG_ 525 ACS2_Version "This signal indicates the version of software";
CM_ SG_ 525 ACS2_LiveCounter "The Livecounter is used to check the signal consistency of the messages";
CM_ SG_ 525 ACS2_ButtonJerk "This signal indicates the state of Jerk Button";
CM_ SG_ 525 ACS2_Checksum "The checksum is used to check whether the data transmission errors";
CM_ SG_ 525 ACS2_Button3 "This signal indicates the state of Button2";
CM_ SG_ 525 ACS2_Button2 "This signal indicates the state of Button2";
CM_ SG_ 525 ACS2_Button1 "This signal indicates the state of Button1";
CM_ SG_ 339 ACU3_EPBControlFlag "This signal is the status of the braking control request";
CM_ SG_ 339 ACU3_GearTarget "This signal is gear request";
CM_ SG_ 339 ACU3_GearControlFlag "This signal is the status of the gear control request";
CM_ SG_ 339 ACU3_BrakingTargetPressure "This signal is deceleration request for wheel brake";
CM_ SG_ 339 ACU3_BrakingTargetDeceleration "This signal is deceleration request for wheel brake";
CM_ SG_ 339 ACU3_BrakingControlFlag "This signal is the status of the braking control request";
CM_ SG_ 339 ACU3_LiveCounter "The Livecounter is used to check the signal consistency of the messages";
CM_ SG_ 339 ACU3_Checksum "The checksum is used to check whether the data transmission errors";
CM_ SG_ 529 VCU2_MasterCylinderPressure "The signal indicates the actual pressure in the master cylinder.";
CM_ SG_ 529 VCU2_BrakePedalSt "This signal indicates the brake pedal status.";
CM_ SG_ 529 VCU2_VehicleSpeed "The signal describes the raw vehicle speed calculated by ABS.";
CM_ SG_ 529 VCU2_DrivingDirection "The signal indicates driving direction of the vehicle.";
CM_ SG_ 529 VCU2_CalAccelerationPedalPositio "This signal indicates the calculated acceleration pedal position in cruise control mode.";
CM_ SG_ 529 VCU2_AccelPedalPosition "This signal indicates the actual acceleration pedal position";
CM_ SG_ 529 VCU2_LiveCounter "The Livecounter is used to check the signal consistency of the messages";
CM_ SG_ 529 VCU2_Checksum "The checksum is used to check whether the data transmission errors";
CM_ SG_ 338 ACU2_DrivingTargetTorque "This signal is acceleration pedal position request";
CM_ SG_ 338 ACU2_DrivingTargetThrottle "This signal is acceleration pedal position request";
CM_ SG_ 338 ACU2_DrivingControlFlag "This signal is the status of the driving control request";
CM_ SG_ 338 ACU2_DrivingTargetAcceleration "This signal is acceleration pedal position request";
CM_ SG_ 338 ACU2_LiveCounter "The Livecounter is used to check the signal consistency of the messages";
CM_ SG_ 338 ACU2_Checksum "The checksum is used to check whether the data transmission errors";
CM_ SG_ 524 ACS1_SteeringStateMachine "This signal indicates the state machine of steering.";
CM_ SG_ 524 ACS1_GearStateMachine "This signal indicates the state machine of gear.";
CM_ SG_ 524 ACS1_DrivingStateMachine "This signal indicates the state machine of driving.";
CM_ SG_ 524 ACS1_BrakingStateMachine "This signal indicates the state machine of braking.";
CM_ SG_ 524 ACS1_GearTakeOverSt "This signal indicates the gear is under maunal taking over.";
CM_ SG_ 524 ACS1_GearFailureSt "This signal indicates the gear is in fault status";
CM_ SG_ 524 ACS1_GearAutoControlSt "This signal indicates the gear is under automatical control or not.";
CM_ SG_ 524 ACS1_SteeringTakeOverSt "This signal indicates the steering is under maunal taking over.";
CM_ SG_ 524 ACS1_SteeringFailureSt "This signal indicates the steering is in fault status";
CM_ SG_ 524 ACS1_SteeringAutoControlSt "This signal indicates the steering is under automatical control or not.";
CM_ SG_ 524 ACS1_LiveCounter "The Livecounter is used to check the signal consistency of the messages";
CM_ SG_ 524 ACS1_DrivingTakeOverSt "This signal indicates the driving is under maunal taking over.";
CM_ SG_ 524 ACS1_DrivingFailureSt "This signal indicates the driving is in fault status";
CM_ SG_ 524 ACS1_DrivingAutoControlSt "This signal indicates the driving is under automatical control or not.";
CM_ SG_ 524 ACS1_Checksum "The checksum is used to check whether the data transmission errors";
CM_ SG_ 524 ACS1_BrakingTakeOverSt "This signal indicates the braking is under maunal taking over.";
CM_ SG_ 524 ACS1_BrakingFailureSt "This signal indicates the braking is in fault status";
CM_ SG_ 524 ACS1_BrakingAutoControlSt "This signal indicates the braking is under automatical control or not.";
CM_ SG_ 337 ACU1_SteeringTargetTorque "This signal is steering torque request";
CM_ SG_ 337 ACU1_SteeringTargetSpeed "This signal is steering speed request";
CM_ SG_ 337 ACU1_SteeringControlFlag "This signal is the status of steering control request";
CM_ SG_ 337 ACU1_SteeringTargetAngle "This signal is steering angle request";
CM_ SG_ 337 ACU1_LiveCounter "The Livecounter is used to check the signal consistency of the messages";
CM_ SG_ 337 ACU1_Checksum "The checksum is used to check whether the data transmission errors";
CM_ SG_ 528 VCU1_OverlayInputTorque "The signal indicates the actual applied overlay toque in EPS.";
CM_ SG_ 528 VCU1_HandSteeringTorque "The signal indicates the torque measured by the torque sensor at the steering wheel";
CM_ SG_ 528 VCU1_LiveCounter "The Livecounter is used to check the signal consistency of the messages";
CM_ SG_ 528 VCU1_Checksum "The checksum is used to check whether the data transmission errors";
CM_ SG_ 528 VCU1_SteeringSpeed "This signal indicates the teering wheel rotation speed. anticlockwise=negative, clockwise=positive";
CM_ SG_ 528 VCU1_SteeringAngle "This signal indicates the angle of steering wheel. anticlockwise=negative, clockwise=positive";
CM_ SG_ 616 GW1_LiveCounter "The Livecounter is used to check the signal consistency of the messages";
CM_ SG_ 616 GW1_Checksum "The checksum is used to check whether the data transmission errors";
CM_ SG_ 616 GW1_OdometerValue "This signal is drive distance since prime start";
CM_ SG_ 616 GW1_IgnitionOffTime "Indicates the time between last KL15 Off and this KL15 on";
CM_ SG_ 616 GW1_FuelValue "This signal indicates fuel value, used for powertrain diagnostic.";
CM_ SG_ 609 WS2_LiveCounter "The Livecounter is used to check the signal consistency of the messages";
CM_ SG_ 609 WS2_Checksum "The checksum is used to check whether the data transmission errors";
CM_ SG_ 609 WS2_WheelSpeedDirection_RR "This signal is the the rear right  wheel speed direction.";
CM_ SG_ 609 WS2_WheelSpeedDirection_RL "This signal is the the rear left wheel speed direction.";
CM_ SG_ 609 WS2_WheelSpeedDirection_FR "This signal is the the front right wheel speed direction.";
CM_ SG_ 609 WS2_WheelSpeedDirection_FL "This signal is the the front left wheel speed direction.";
CM_ SG_ 609 WS2_WheelPulse_RR "This signal is the rear right wheel speed pulse(raw data).";
CM_ SG_ 609 WS2_WheelPulse_RL "This signal is the rear left wheel speed pulse(raw data).";
CM_ SG_ 609 WS2_WheelPulse_FR "This signal is the front right wheel speed pulse(raw data).";
CM_ SG_ 609 WS2_WheelPulse_FL "This signal is the front left wheel speed pulse(raw data).";
CM_ SG_ 672 BCM1_PassengerSideBuckle "The signal is sent to indicate the Driver Seat Belt is buckled or Unbuckled.";
CM_ SG_ 672 BCM1_WiperSpeed "This signal informs about the wiper speed requested by the Sensor according to rain intensity or other factors";
CM_ SG_ 672 BCM1_PositionLightSt "The signal indicates the status of position light.";
CM_ SG_ 672 BCM1_MirrorFoldSt_FR "Fold status of right mirror";
CM_ SG_ 672 BCM1_MirrorFoldSt_FL "Fold status of left mirror";
CM_ SG_ 672 BCM1_DriverSideBuckle "The signal is sent to indicate the Driver Seat Belt is buckled or Unbuckled.";
CM_ SG_ 672 BCM1_WiperStatus "The signal indicates front wiper status.";
CM_ SG_ 672 BCM1_LuggageDoorSt "This signal indicates luggage door status";
CM_ SG_ 672 BCM1_LowBeamSt "The signal  indicates the status of low beam indicator.";
CM_ SG_ 672 BCM1_HighBeamSt "The signal  indicates the status of high beam indicator.";
CM_ SG_ 672 BCM1_EngHoodSt "This signal shows engine hood status.";
CM_ SG_ 672 BCM1_RRDoorLockSt "This signal indicates the lock state of RR door.";
CM_ SG_ 672 BCM1_RRDoorSt "This signal indicates the state of RR door.";
CM_ SG_ 672 BCM1_RLDoorLockSt "This signal indicates the lock state of RL door.";
CM_ SG_ 672 BCM1_RLDoorSt "This signal indicates the state of RL door.";
CM_ SG_ 672 BCM1_PassengerDoorLockSt "This signal indicates the lock state of passenger door.";
CM_ SG_ 672 BCM1_PassengerDoorSt "This signal indicates the state of passenger door.";
CM_ SG_ 672 BCM1_DriverDoorLockSt "This signal indicates the lock state of driver door.";
CM_ SG_ 672 BCM1_DriverDoorSt "This signal indicates the state of driver door.";
CM_ SG_ 672 BCM1_LiveCounter "The Livecounter is used to check the signal consistency of the messages";
CM_ SG_ 672 BCM1_Checksum "The checksum is used to check whether the data transmission errors";
CM_ SG_ 672 BCM1_SteeringLightSt "The signal indicates the driving status of the turn light.";
CM_ SG_ 672 BCM1_HazardLightSt "The signal indicates Indicates the Hazard Warning is active or not";
CM_ SG_ 608 WS1_WheelSpeed_RR "This signal is rear right wheel speed which sent by ABS without filtering.";
CM_ SG_ 608 WS1_WheelSpeed_RL "This signal is rear left wheel speed which sent by ABS without filtering.";
CM_ SG_ 608 WS1_WheelSpeed_FR "This signal is front right wheel speed which sent by ABS without filtering.";
CM_ SG_ 608 WS1_WheelSpeed_FL "This signal is front left wheel speed which sent by ABS without filtering.";
CM_ SG_ 947 UR3_LiveCounter "The Livecounter is used to check the signal consistency of the messages";
CM_ SG_ 947 UR3_DistanceValue_RRS "This signal indicates the obstacle detection distance by rear right side radar";
CM_ SG_ 947 UR3_DistanceValue_RLS "This signal indicates the obstacle detection distance by rear left side radar";
CM_ SG_ 947 UR3_DistanceValue_FRS "This signal indicates the obstacle detection distance by front right side radar";
CM_ SG_ 947 UR3_DistanceValue_FLS "This signal indicates the obstacle detection distance by front left side radar";
CM_ SG_ 947 UR3_Checksum "The checksum is used to check whether the data transmission errors";
CM_ SG_ 946 UR2_LiveCounter "The Livecounter is used to check the signal consistency of the messages";
CM_ SG_ 946 UR2_DistanceValue_RR "This signal indicates the obstacle detection distance by rear right radar";
CM_ SG_ 946 UR2_DistanceValue_RMR "This signal indicates the obstacle detection distance by rear middle right radar";
CM_ SG_ 946 UR2_DistanceValue_RML "This signal indicates the obstacle detection distance by rear middle left radar";
CM_ SG_ 946 UR2_DistanceValue_RL "This signal indicates the obstacle detection distance by rear left radar";
CM_ SG_ 946 UR2_Checksum "The checksum is used to check whether the data transmission errors";
CM_ SG_ 945 UR1_LiveCounter "The Livecounter is used to check the signal consistency of the messages";
CM_ SG_ 945 UR1_DistanceValue_FR "This signal indicates the obstacle detection distance by front right radar";
CM_ SG_ 945 UR1_DistanceValue_FMR "This signal indicates the obstacle detection distance by front middle right radar";
CM_ SG_ 945 UR1_DistanceValue_FML "This signal indicates the obstacle detection distance by front middle left radar";
CM_ SG_ 945 UR1_DistanceValue_FL "This signal indicates the obstacle detection distance by front left radar";
CM_ SG_ 945 UR1_Checksum "The checksum is used to check whether the data transmission errors";
BA_DEF_ SG_  "GenSigNeed" INT 0 1;
BA_DEF_ SG_  "GenSigExplanation" STRING ;
BA_DEF_ BO_  "GenMsgType" STRING ;
BA_DEF_  "BusType" STRING ;
BA_DEF_  "Baudrate" INT 0 1000000;
BA_DEF_  "VersionDay" INT 1 31;
BA_DEF_  "VersionMonth" INT 1 12;
BA_DEF_  "VersionYear" INT 2000 2099;
BA_DEF_  "DBName" STRING ;
BA_DEF_ BO_  "GenMsgCycleTime" INT 0 50000;
BA_DEF_ SG_  "SystemSignalLongSymbol" STRING ;
BA_DEF_DEF_  "GenSigNeed" 0;
BA_DEF_DEF_  "GenSigExplanation" "";
BA_DEF_DEF_  "GenMsgType" "N";
BA_DEF_DEF_  "BusType" "";
BA_DEF_DEF_  "Baudrate" 500000;
BA_DEF_DEF_  "VersionDay" 1;
BA_DEF_DEF_  "VersionMonth" 1;
BA_DEF_DEF_  "VersionYear" 2020;
BA_DEF_DEF_  "DBName" "VENUS";
BA_DEF_DEF_  "GenMsgCycleTime" 10;
BA_DEF_DEF_  "SystemSignalLongSymbol" "";
BA_ "VersionDay" 12;
BA_ "VersionMonth" 10;
BA_ "VersionYear" 2021;
BA_ "BusType" "CAN";
BA_ "DBName" "WIRE";
BA_ "GenMsgType" BO_ 673 "R";
BA_ "GenMsgType" BO_ 512 "R";
BA_ "GenMsgType" BO_ 530 "R";
BA_ "GenMsgCycleTime" BO_ 653 100;
BA_ "GenMsgCycleTime" BO_ 652 100;
BA_ "GenMsgType" BO_ 648 "T";
BA_ "GenMsgCycleTime" BO_ 648 100;
BA_ "GenMsgType" BO_ 340 "R";
BA_ "GenMsgCycleTime" BO_ 340 100;
BA_ "GenMsgType" BO_ 525 "T";
BA_ "GenMsgCycleTime" BO_ 525 20;
BA_ "GenMsgType" BO_ 339 "R";
BA_ "GenMsgType" BO_ 529 "R";
BA_ "GenMsgType" BO_ 338 "R";
BA_ "GenMsgType" BO_ 524 "T";
BA_ "GenMsgType" BO_ 337 "R";
BA_ "GenMsgType" BO_ 528 "T";
BA_ "GenMsgCycleTime" BO_ 616 100;
BA_ "GenMsgType" BO_ 616 "T";
BA_ "GenMsgType" BO_ 609 "T";
BA_ "GenMsgType" BO_ 672 "T";
BA_ "GenMsgCycleTime" BO_ 672 100;
BA_ "GenMsgType" BO_ 608 "T";
BA_ "GenMsgCycleTime" BO_ 947 20;
BA_ "GenMsgCycleTime" BO_ 946 20;
BA_ "GenMsgCycleTime" BO_ 945 20;
BA_ "GenSigNeed" SG_ 3221225472 DCDC1_Temperature 1;
BA_ "GenSigNeed" SG_ 3221225472 DCDC1_Status 1;
BA_ "GenSigNeed" SG_ 3221225472 DCDC1_OutputVoltage 1;
BA_ "GenSigNeed" SG_ 3221225472 DCDC1_OutputCurrent 1;
BA_ "GenSigExplanation" SG_ 3221225472 DCDC1_LiveCounter "»îÔ¾¼ÆÊýÆ÷";
BA_ "GenSigNeed" SG_ 3221225472 DCDC1_InputVoltage 1;
BA_ "GenSigNeed" SG_ 3221225472 DCDC1_InputCurrent 1;
BA_ "GenSigExplanation" SG_ 3221225472 DCDC1_Checksum "Ð£ÑéºÍ";
BA_ "GenSigNeed" SG_ 3221225472 MCU1_TMTorque 1;
BA_ "GenSigNeed" SG_ 3221225472 MCU1_TMTemperature 1;
BA_ "GenSigNeed" SG_ 3221225472 MCU1_TMSpeed 1;
BA_ "GenSigNeed" SG_ 3221225472 MCU1_TMCapacitanceVoltage 1;
BA_ "GenSigExplanation" SG_ 3221225472 MCU1_LiveCounter "»îÔ¾¼ÆÊýÆ÷";
BA_ "GenSigExplanation" SG_ 3221225472 MCU1_Checksum "Ð£ÑéºÍ";
BA_ "GenSigExplanation" SG_ 3221225472 ESC1_LiveCounter "»îÔ¾¼ÆÊýÆ÷";
BA_ "GenSigExplanation" SG_ 3221225472 ESC1_Checksum "Ð£ÑéºÍ";
BA_ "GenSigNeed" SG_ 3221225472 ESC1_YawRate 1;
BA_ "GenSigExplanation" SG_ 3221225472 ESC1_YawRate "Æ«º½ÂÊ£¨ÕýÖµË³Ê±Õë£©";
BA_ "GenSigNeed" SG_ 3221225472 ESC1_AccelerationX 1;
BA_ "GenSigExplanation" SG_ 3221225472 ESC1_AccelerationX "×ÝÏò¼ÓËÙ¶È£¨ÕýÖµÏòÇ°£©";
BA_ "GenSigNeed" SG_ 3221225472 ESC1_AccelerationY 1;
BA_ "GenSigExplanation" SG_ 3221225472 ESC1_AccelerationY "ºáÏò¼ÓËÙ¶È£¨ÕýÖµÏòÓÒ£©";
BA_ "GenSigExplanation" SG_ 3221225472 ENV1_LiveCounter "»îÔ¾¼ÆÊýÆ÷";
BA_ "GenSigExplanation" SG_ 3221225472 ENV1_Checksum "Ð£ÑéºÍ";
BA_ "GenSigExplanation" SG_ 3221225472 ENV1_TimeYear "Äê";
BA_ "GenSigNeed" SG_ 3221225472 ENV1_TimeYear 1;
BA_ "GenSigExplanation" SG_ 3221225472 ENV1_TimeSecond "Ãë";
BA_ "GenSigNeed" SG_ 3221225472 ENV1_TimeSecond 1;
BA_ "GenSigExplanation" SG_ 3221225472 ENV1_TimeMonth "ÔÂ";
BA_ "GenSigNeed" SG_ 3221225472 ENV1_TimeMonth 1;
BA_ "GenSigExplanation" SG_ 3221225472 ENV1_TimeMinute "·Ö";
BA_ "GenSigNeed" SG_ 3221225472 ENV1_TimeMinute 1;
BA_ "GenSigExplanation" SG_ 3221225472 ENV1_TimeHour "Ê±";
BA_ "GenSigNeed" SG_ 3221225472 ENV1_TimeHour 1;
BA_ "GenSigExplanation" SG_ 3221225472 ENV1_TimeDay "ÈÕ";
BA_ "GenSigNeed" SG_ 3221225472 ENV1_TimeDay 1;
BA_ "GenSigExplanation" SG_ 3221225472 ENV1_RainIntensity "½µÓêÇ¿¶È";
BA_ "GenSigNeed" SG_ 3221225472 ENV1_RainIntensity 1;
BA_ "GenSigExplanation" SG_ 3221225472 ENV1_BrightnessH "¹âÕÕÇ¿¶È";
BA_ "GenSigNeed" SG_ 3221225472 ENV1_BrightnessH 1;
BA_ "GenSigNeed" SG_ 3221225472 EPS1_LKAStatus 1;
BA_ "GenSigExplanation" SG_ 3221225472 EPS1_LKAStatus "LKA×´Ì¬";
BA_ "GenSigNeed" SG_ 3221225472 EPS1_ElectricLoad 1;
BA_ "GenSigExplanation" SG_ 3221225472 EPS1_ElectricLoad "×ªÏòµç»ú¸ºÔØµçÁ÷";
BA_ "GenSigNeed" SG_ 3221225472 EPS1_APAErrorStatus 1;
BA_ "GenSigExplanation" SG_ 3221225472 EPS1_APAErrorStatus "APA¹ÊÕÏ×´Ì¬";
BA_ "GenSigNeed" SG_ 3221225472 EPS1_APARequestFeedback 1;
BA_ "GenSigExplanation" SG_ 3221225472 EPS1_APARequestFeedback "APA×´Ì¬·´À¡";
BA_ "GenSigNeed" SG_ 3221225472 EPS1_APAAbortFeedback 1;
BA_ "GenSigExplanation" SG_ 3221225472 EPS1_APAAbortFeedback "APAÒì³£×´Ì¬";
BA_ "GenSigNeed" SG_ 3221225472 EPS1_OverlayInputTorque 1;
BA_ "GenSigExplanation" SG_ 3221225472 EPS1_OverlayInputTorque "LKAÅ¤¾Ø·´À¡";
BA_ "GenSigExplanation" SG_ 3221225472 EPS1_LiveCounter "»îÔ¾¼ÆÊýÆ÷";
BA_ "GenSigNeed" SG_ 3221225472 EPS1_HandSteeringTorque 1;
BA_ "GenSigExplanation" SG_ 3221225472 EPS1_HandSteeringTorque "·½ÏòÅÌ¸ÉÔ¤×ª¾Ø";
BA_ "GenSigExplanation" SG_ 3221225472 EPS1_Checksum "Ð£ÑéºÍ";
BA_ "GenSigNeed" SG_ 3221225472 A_Test_Data 1;
BA_ "GenSigNeed" SG_ 3221225472 BDFL_MirLeftButton_ST 1;
BA_ "GenSigNeed" SG_ 3221225472 BDFL_MirButtonUP_ST 1;
BA_ "GenSigNeed" SG_ 3221225472 BDFL_MirButtonRight_ST 1;
BA_ "GenSigNeed" SG_ 3221225472 BDFL_MirButtonLeft_ST 1;
BA_ "GenSigNeed" SG_ 3221225472 BDFL_MirButtonDown_ST 1;
BA_ "GenSigNeed" SG_ 3221225472 BDFL_UnLockButton_ST 1;
BA_ "GenSigNeed" SG_ 3221225472 BDFL_LockButton_ST 1;
BA_ "GenSigNeed" SG_ 3221225472 BDFL_BootButtonFL_ST 1;
BA_ "GenSigNeed" SG_ 3221225472 BDFL_WinButtonRR_ST 1;
BA_ "GenSigNeed" SG_ 3221225472 BDFL_WinButtonRL_ST 1;
BA_ "GenSigNeed" SG_ 3221225472 BDFL_WinButtonFR_ST 1;
BA_ "GenSigNeed" SG_ 3221225472 BDFL_WinButtonFL_ST 1;
BA_ "GenSigNeed" SG_ 530 VCU3_ThrottleVoltage 1;
BA_ "GenSigNeed" SG_ 530 VCU3_MainSwitch 1;
BA_ "GenSigNeed" SG_ 530 VCU3_IncreaseSpeedSwitch 1;
BA_ "GenSigNeed" SG_ 530 VCU3_IncreaseDistanceSwitch 1;
BA_ "GenSigNeed" SG_ 530 VCU3_DecreaseSpeedSwitch 1;
BA_ "GenSigNeed" SG_ 530 VCU3_DecreaseDistanceSwitch 1;
BA_ "GenSigNeed" SG_ 530 VCU3_CancelSwitch 1;
BA_ "GenSigNeed" SG_ 530 VCU3_GearSecurityButton 1;
BA_ "GenSigNeed" SG_ 530 VCU3_GearParkButton 1;
BA_ "GenSigNeed" SG_ 530 VCU3_GearLeverPosition 1;
BA_ "GenSigNeed" SG_ 530 VCU3_EPBSwitch 1;
BA_ "GenSigNeed" SG_ 530 VCU3_VacuumPressure 1;
BA_ "GenSigNeed" SG_ 530 VCU3_LeverInfo 1;
BA_ "GenSigNeed" SG_ 530 VCU3_EPBStatus 1;
BA_ "GenSigNeed" SG_ 530 VCU3_ActualGear 1;
BA_ "GenSigNeed" SG_ 653 CHU2_RemainingChargeTime 1;
BA_ "GenSigNeed" SG_ 653 CHU2_InsulationMonitorWarning 1;
BA_ "GenSigNeed" SG_ 653 CHU2_InstantPowerConsumption 1;
BA_ "GenSigNeed" SG_ 653 CHU2_ChargeStationStatus 1;
BA_ "GenSigNeed" SG_ 653 CHU2_ChargeStationParameterConfi 1;
BA_ "SystemSignalLongSymbol" SG_ 653 CHU2_ChargeStationParameterConfi "CHU2_ChargeStationParameterConfigStatus";
BA_ "GenSigNeed" SG_ 653 CHU2_ChargeStationOutputVoltage 1;
BA_ "GenSigNeed" SG_ 653 CHU2_ChargeStationOutputCurrent 1;
BA_ "GenSigNeed" SG_ 653 CHU2_ChargeStationHandShakeStatu 1;
BA_ "SystemSignalLongSymbol" SG_ 653 CHU2_ChargeStationHandShakeStatu "CHU2_ChargeStationHandShakeStatus";
BA_ "GenSigNeed" SG_ 652 CHU1_Temperature 1;
BA_ "GenSigNeed" SG_ 652 CHU1_Status 1;
BA_ "GenSigNeed" SG_ 652 CHU1_RechargeRequest 1;
BA_ "GenSigNeed" SG_ 652 CHU1_OutputVoltage 1;
BA_ "GenSigNeed" SG_ 652 CHU1_OutputCurrent 1;
BA_ "GenSigNeed" SG_ 652 CHU1_Mode 1;
BA_ "GenSigNeed" SG_ 652 CHU1_CPStatus 1;
BA_ "GenSigNeed" SG_ 648 BMS1_HeatingRequest 1;
BA_ "GenSigNeed" SG_ 648 BMS1_BatteryPackVoltage 1;
BA_ "GenSigNeed" SG_ 648 BMS1_BatteryPackTemperature 1;
BA_ "GenSigNeed" SG_ 648 BMS1_BatteryPackSOH 1;
BA_ "GenSigNeed" SG_ 648 BMS1_BatteryPackSOC 1;
BA_ "GenSigNeed" SG_ 648 BMS1_BatteryPackCurrent 1;
BA_ "GenSigNeed" SG_ 340 ACU4_Lock_Request 1;
BA_ "GenSigNeed" SG_ 340 ACU4_FRWindow_Request 1;
BA_ "GenSigNeed" SG_ 340 ACU4_FLWindow_Request 1;
BA_ "GenSigNeed" SG_ 340 ACU4_BeamLampRequest 1;
BA_ "GenSigNeed" SG_ 340 ACU4_SteeringLampRequest 1;
BA_ "GenSigNeed" SG_ 340 ACU4_HazardLampRequest 1;
BA_ "GenSigNeed" SG_ 525 ACS2_ButtonJerk 1;
BA_ "GenSigNeed" SG_ 525 ACS2_Button3 1;
BA_ "GenSigNeed" SG_ 525 ACS2_Button2 1;
BA_ "GenSigNeed" SG_ 525 ACS2_Button1 1;
BA_ "GenSigNeed" SG_ 339 ACU3_EPBControlFlag 1;
BA_ "GenSigNeed" SG_ 339 ACU3_GearTarget 1;
BA_ "GenSigNeed" SG_ 339 ACU3_GearControlFlag 1;
BA_ "GenSigNeed" SG_ 339 ACU3_BrakingTargetPressure 1;
BA_ "GenSigNeed" SG_ 339 ACU3_BrakingControlFlag 1;
BA_ "GenSigNeed" SG_ 529 VCU2_BrakePedalSt 1;
BA_ "GenSigNeed" SG_ 529 VCU2_VehicleSpeed 1;
BA_ "GenSigNeed" SG_ 529 VCU2_CalAccelerationPedalPositio 1;
BA_ "SystemSignalLongSymbol" SG_ 529 VCU2_CalAccelerationPedalPositio "VCU2_CalAccelerationPedalPosition";
BA_ "GenSigNeed" SG_ 529 VCU2_AccelPedalPosition 1;
BA_ "GenSigNeed" SG_ 338 ACU2_DrivingTargetSpeed 1;
BA_ "GenSigNeed" SG_ 338 ACU2_DrivingControlFlag 1;
BA_ "GenSigNeed" SG_ 524 ACS1_SteeringStateMachine 1;
BA_ "GenSigNeed" SG_ 524 ACS1_GearStateMachine 1;
BA_ "GenSigNeed" SG_ 524 ACS1_DrivingStateMachine 1;
BA_ "GenSigNeed" SG_ 524 ACS1_BrakingStateMachine 1;
BA_ "GenSigNeed" SG_ 524 ACS1_GearTakeOverSt 1;
BA_ "GenSigNeed" SG_ 524 ACS1_GearFailureSt 1;
BA_ "GenSigNeed" SG_ 524 ACS1_GearAutoControlSt 1;
BA_ "GenSigNeed" SG_ 524 ACS1_SteeringTakeOverSt 1;
BA_ "GenSigNeed" SG_ 524 ACS1_SteeringFailureSt 1;
BA_ "GenSigNeed" SG_ 524 ACS1_SteeringAutoControlSt 1;
BA_ "GenSigNeed" SG_ 524 ACS1_DrivingTakeOverSt 1;
BA_ "GenSigNeed" SG_ 524 ACS1_DrivingFailureSt 1;
BA_ "GenSigNeed" SG_ 524 ACS1_DrivingAutoControlSt 1;
BA_ "GenSigNeed" SG_ 524 ACS1_BrakingTakeOverSt 1;
BA_ "GenSigNeed" SG_ 524 ACS1_BrakingFailureSt 1;
BA_ "GenSigNeed" SG_ 524 ACS1_BrakingAutoControlSt 1;
BA_ "GenSigNeed" SG_ 337 ACU1_SteeringTargetTorque 1;
BA_ "GenSigNeed" SG_ 337 ACU1_SteeringTargetSpeed 1;
BA_ "GenSigNeed" SG_ 337 ACU1_SteeringControlFlag 1;
BA_ "GenSigNeed" SG_ 337 ACU1_SteeringTargetAngle 1;
BA_ "GenSigNeed" SG_ 528 VCU1_HandSteeringTorque 1;
BA_ "GenSigNeed" SG_ 528 VCU1_SteeringAngle 1;
BA_ "GenSigNeed" SG_ 616 GW1_EVReady 1;
BA_ "GenSigNeed" SG_ 616 GW1_HVReady 1;
BA_ "GenSigNeed" SG_ 616 GW1_OdometerValue 1;
BA_ "GenSigNeed" SG_ 616 GW1_IgnitionOffTime 1;
BA_ "GenSigNeed" SG_ 616 GW1_FuelValue 1;
BA_ "GenSigNeed" SG_ 609 WS2_WheelSpeedDirection_RR 1;
BA_ "GenSigNeed" SG_ 609 WS2_WheelSpeedDirection_RL 1;
BA_ "GenSigNeed" SG_ 609 WS2_WheelSpeedDirection_FR 1;
BA_ "GenSigNeed" SG_ 609 WS2_WheelSpeedDirection_FL 1;
BA_ "GenSigNeed" SG_ 609 WS2_WheelPulse_RR 1;
BA_ "GenSigNeed" SG_ 609 WS2_WheelPulse_RL 1;
BA_ "GenSigNeed" SG_ 609 WS2_WheelPulse_FR 1;
BA_ "GenSigNeed" SG_ 609 WS2_WheelPulse_FL 1;
BA_ "GenSigNeed" SG_ 672 BCM1_PassengerSideBuckle 1;
BA_ "GenSigNeed" SG_ 672 BCM1_WiperSpeed 1;
BA_ "GenSigNeed" SG_ 672 BCM1_PositionLightSt 1;
BA_ "GenSigNeed" SG_ 672 BCM1_MirrorFoldSt_FR 1;
BA_ "GenSigNeed" SG_ 672 BCM1_MirrorFoldSt_FL 1;
BA_ "GenSigNeed" SG_ 672 BCM1_DriverSideBuckle 1;
BA_ "GenSigNeed" SG_ 672 BCM1_WiperStatus 1;
BA_ "GenSigNeed" SG_ 672 BCM1_LuggageDoorSt 1;
BA_ "GenSigNeed" SG_ 672 BCM1_LowBeamSt 1;
BA_ "GenSigNeed" SG_ 672 BCM1_HighBeamSt 1;
BA_ "GenSigNeed" SG_ 672 BCM1_EngHoodSt 1;
BA_ "GenSigNeed" SG_ 672 BCM1_RRDoorLockSt 1;
BA_ "GenSigNeed" SG_ 672 BCM1_RRDoorSt 1;
BA_ "GenSigNeed" SG_ 672 BCM1_RLDoorLockSt 1;
BA_ "GenSigNeed" SG_ 672 BCM1_RLDoorSt 1;
BA_ "GenSigNeed" SG_ 672 BCM1_PassengerDoorLockSt 1;
BA_ "GenSigNeed" SG_ 672 BCM1_PassengerDoorSt 1;
BA_ "GenSigNeed" SG_ 672 BCM1_DriverDoorLockSt 1;
BA_ "GenSigNeed" SG_ 672 BCM1_DriverDoorSt 1;
BA_ "GenSigNeed" SG_ 672 BCM1_SteeringLightSt 1;
BA_ "GenSigNeed" SG_ 672 BCM1_HazardLightSt 1;
BA_ "GenSigNeed" SG_ 608 WS1_WheelSpeed_RR 1;
BA_ "GenSigNeed" SG_ 608 WS1_WheelSpeed_RL 1;
BA_ "GenSigNeed" SG_ 608 WS1_WheelSpeed_FR 1;
BA_ "GenSigNeed" SG_ 608 WS1_WheelSpeed_FL 1;
VAL_ 3221225472 EPS1_LKAStatus 7 "Reserved" 6 "Reserved" 5 "Reserved" 4 "Not Configured" 3 "Permanently fail" 2 "Active" 1 "Available for control" 0 "Temporary inhibit" ;
VAL_ 3221225472 EPS1_APAErrorStatus 1 "Error" 0 "No Error" ;
VAL_ 3221225472 EPS1_APARequestFeedback 1 "Enable" 0 "Disable" ;
VAL_ 3221225472 EPS1_APAAbortFeedback 31 "Reserved" 30 "Reserved" 29 "Reserved" 28 "Reserved" 27 "Reserved" 26 "Reserved" 25 "Reserved" 24 "Reserved" 23 "Reserved" 22 "Reserved" 21 "Reserved" 20 "Reserved" 19 "Reserved" 18 "Difference of the first Steering Wheel Angle Req signal and Steering Wheel Angle exceeds limits" 17 "Handshaking timeout" 16 "EPS control active received without handshaking" 15 "EPS system critical failure,no steering assistance" 14 "Vehicle Speed exceeds limits when in control" 13 "Difference of Steering Wheel Angle Req and Steering Wheel Angle exceeds limits" 12 "Difference of the two neighboring Steering Wheel Angle Req signals exceeds limits" 11 "EPS control Req received when in contol" 10 "Gear signal invalid or timeout" 9 "EPS internal failure with limited steering assistance" 8 "Steering Wheel Angle speed exceeds limits when in control" 7 "CAN Bus Off" 6 "HAD control signal invalid or timeout" 5 "Steering Wheel Angle invalid or timeout" 4 "Steering Wheel Angle Speed Req exceeds limits" 3 "Steering Wheel Angle Req exceeds limits" 2 "Vehicle Speed invalid or timeout" 1 "Recoverable interruption" 0 "No driving interuption" ;
VAL_ 530 VCU3_MainSwitch 1 "Active" 0 "Inactive" ;
VAL_ 530 VCU3_IncreaseSpeedSwitch 1 "Active" 0 "Inactive" ;
VAL_ 530 VCU3_IncreaseDistanceSwitch 1 "Active" 0 "Inactive" ;
VAL_ 530 VCU3_DecreaseSpeedSwitch 1 "Active" 0 "Inactive" ;
VAL_ 530 VCU3_DecreaseDistanceSwitch 1 "Active" 0 "Inactive" ;
VAL_ 530 VCU3_CancelSwitch 1 "Active" 0 "Inactive" ;
VAL_ 530 VCU3_GearSecurityButton 1 "Pressed" 0 "No Pressed" ;
VAL_ 530 VCU3_GearParkButton 1 "Pressed" 0 "No Pressed" ;
VAL_ 530 VCU3_GearLeverPosition 7 "Invalid Value" 6 "Reserved" 5 "Reserved" 4 "Position sub2" 3 "Position sub1" 2 "Position add2" 1 "Position add1" 0 "Position 0" ;
VAL_ 530 VCU3_EPBSwitch 3 "Reserved" 2 "Down" 1 "Up" 0 "No Press" ;
VAL_ 530 VCU3_LeverInfo 15 "Invalid Value" 14 "No Connection" 13 "Reserved" 12 "Reserved" 11 "Reserved" 10 "Reserved" 9 "Reserved" 8 "B" 7 "E" 6 "W" 5 "M" 4 "S" 3 "D" 2 "N" 1 "R" 0 "P" ;
VAL_ 530 VCU3_EPBStatus 3 "Unknow" 2 "Locked" 1 "Releasing or Locking" 0 "Released" ;
VAL_ 530 VCU3_ActualGear 15 "Invalid Value" 14 "No Connection" 13 "Reserved" 12 "Reserved" 11 "Reserved" 10 "8" 9 "7" 8 "6" 7 "5" 6 "4" 5 "3" 4 "2" 3 "1" 2 "N" 1 "R" 0 "P" ;
VAL_ 340 ACU4_SteeringLampRequest 3 "Reserved" 2 "Right On" 1 "Left On" 0 "Off" ;
VAL_ 340 ACU4_HazardLampRequest 1 "On" 0 "Off" ;
VAL_ 525 ACS2_ValidityCAN7 1 "Deactive" 0 "Active" ;
VAL_ 525 ACS2_ValidityCAN6 1 "Deactive" 0 "Active" ;
VAL_ 525 ACS2_ValidityCAN5 1 "Deactive" 0 "Active" ;
VAL_ 525 ACS2_ValidityCAN4 1 "Deactive" 0 "Active" ;
VAL_ 525 ACS2_ValidityCAN3 1 "Deactive" 0 "Active" ;
VAL_ 525 ACS2_ValidityCAN2 1 "Deactive" 0 "Active" ;
VAL_ 525 ACS2_ValidityCAN1 1 "Deactive" 0 "Active" ;
VAL_ 525 ACS2_ValidityCAN0 1 "Deactive" 0 "Active" ;
VAL_ 525 ACS2_ButtonJerk 1 "Press" 0 "No Press" ;
VAL_ 525 ACS2_Button3 1 "Press" 0 "No Press" ;
VAL_ 525 ACS2_Button2 1 "Press" 0 "No Press" ;
VAL_ 525 ACS2_Button1 1 "Press" 0 "No Press" ;
VAL_ 339 ACU3_EPBControlFlag 3 "Reserved" 2 "Lock" 1 "Release" 0 "No Request" ;
VAL_ 339 ACU3_GearTarget 7 "Reserved" 6 "Reserved" 5 "Reserved" 4 "Reserved" 3 "D" 2 "N" 1 "R" 0 "P" ;
VAL_ 339 ACU3_GearControlFlag 1 "Request" 0 "No Request" ;
VAL_ 339 ACU3_BrakingControlFlag 3 "Reserved" 2 "Reserved" 1 "Request" 0 "No Request" ;
VAL_ 529 VCU2_BrakePedalSt 3 "Error" 2 "Reserved" 1 "Actuated" 0 "No Actuated" ;
VAL_ 529 VCU2_DrivingDirection 3 "Invalid Value" 2 "Backward" 1 "Forward" 0 "Stop" ;
VAL_ 338 ACU2_DrivingControlFlag 3 "Reserved" 2 "ReservedSpeed" 1 "RequestThrottle" 0 "No Request" ;
VAL_ 524 ACS1_DrivingStateMachine 7 "ERROR" 6 "EMERGENCY" 5 "INTERVENTION" 4 "IPC" 3 "REMOTE" 2 "MANUAL" 1 "CHECK" 0 "IDLE" ;
VAL_ 524 ACS1_GearTakeOverSt 3 "Reserved" 2 "Active" 1 "Temp Active" 0 "Inactive" ;
VAL_ 524 ACS1_GearFailureSt 3 "Reserved" 2 "HCU Fail" 1 "EGSM Fail" 0 "No Fail" ;
VAL_ 524 ACS1_GearAutoControlSt 3 "Reserved" 2 "Reserved" 1 "Active" 0 "Inactive" ;
VAL_ 524 ACS1_SteeringTakeOverSt 3 "Reserved" 2 "Active" 1 "Temp Active" 0 "Inactive" ;
VAL_ 524 ACS1_SteeringFailureSt 3 "APA Fail" 2 "SAS Fail" 1 "EPS Fail" 0 "No Fail" ;
VAL_ 524 ACS1_SteeringAutoControlSt 3 "Reserved" 2 "Reserved" 1 "Active" 0 "Inactive" ;
VAL_ 524 ACS1_DrivingTakeOverSt 3 "Reserved" 2 "Active" 1 "Temp Active" 0 "Inactive" ;
VAL_ 524 ACS1_DrivingFailureSt 3 "Reserved" 2 "Reserved" 1 "HCU Fail" 0 "No Fail" ;
VAL_ 524 ACS1_DrivingAutoControlSt 3 "Reserved" 2 "Reserved" 1 "Active" 0 "Inactive" ;
VAL_ 524 ACS1_BrakingTakeOverSt 3 "Reserved" 2 "Active" 1 "Temp Active" 0 "Inactive" ;
VAL_ 524 ACS1_BrakingFailureSt 3 "HCU Fail" 2 "SS Fail" 1 "ESP Fail" 0 "No Fail" ;
VAL_ 524 ACS1_BrakingAutoControlSt 3 "Reserved" 2 "Reserved" 1 "Active" 0 "Inactive" ;
VAL_ 337 ACU1_SteeringControlFlag 3 "Reserved" 2 "Reserved" 1 "Request" 0 "No Request" ;
VAL_ 609 WS2_WheelSpeedDirection_RR 3 "Invalid Value" 2 "Backward" 1 "Forward" 0 "Stop" ;
VAL_ 609 WS2_WheelSpeedDirection_RL 3 "Invalid Value" 2 "Backward" 1 "Forward" 0 "Stop" ;
VAL_ 609 WS2_WheelSpeedDirection_FR 3 "Invalid Value" 2 "Backward" 1 "Forward" 0 "Stop" ;
VAL_ 609 WS2_WheelSpeedDirection_FL 3 "Invalid Value" 2 "Backward" 1 "Forward" 0 "Stop" ;
VAL_ 672 BCM1_PassengerSideBuckle 3 "Reserved" 2 "Reserved" 1 "Buckled" 0 "Unbuckled" ;
VAL_ 672 BCM1_WiperSpeed 7 "60 times/min" 6 "57 times/min" 5 "54 times/min" 4 "51 times/min" 3 "48 times/min" 2 "45 times/min" 1 "42 times/min" 0 "No wipe" ;
VAL_ 672 BCM1_PositionLightSt 3 "Reserved" 2 "Reserved" 1 "On" 0 "Off" ;
VAL_ 672 BCM1_MirrorFoldSt_FR 3 "Reserved" 2 "Reserved" 1 "Fold" 0 "Unfold" ;
VAL_ 672 BCM1_MirrorFoldSt_FL 3 "Reserved" 2 "Reserved" 1 "Fold" 0 "Unfold" ;
VAL_ 672 BCM1_DriverSideBuckle 3 "Reserved" 2 "Reserved" 1 "Buckled" 0 "Unbuckled" ;
VAL_ 672 BCM1_WiperStatus 7 "Reserved" 6 "Reserved" 5 "Reserved" 4 "High Speed" 3 "Low Speed" 2 "Interval or Auto lever" 1 "Tip" 0 "Off" ;
VAL_ 672 BCM1_LuggageDoorSt 1 "Open" 0 "Close" ;
VAL_ 672 BCM1_LowBeamSt 3 "Reserved" 2 "Reserved" 1 "On" 0 "Off" ;
VAL_ 672 BCM1_HighBeamSt 3 "Reserved" 2 "Reserved" 1 "On" 0 "Off" ;
VAL_ 672 BCM1_EngHoodSt 1 "Open" 0 "Close" ;
VAL_ 672 BCM1_RRDoorLockSt 3 "Reserved" 2 "Reserved" 1 "Unlock" 0 "Lock" ;
VAL_ 672 BCM1_RRDoorSt 1 "Open" 0 "Close" ;
VAL_ 672 BCM1_RLDoorLockSt 3 "Reserved" 2 "Reserved" 1 "Unlock" 0 "Lock" ;
VAL_ 672 BCM1_RLDoorSt 1 "Open" 0 "Close" ;
VAL_ 672 BCM1_PassengerDoorLockSt 3 "Reserved" 2 "Reserved" 1 "Unlock" 0 "Lock" ;
VAL_ 672 BCM1_PassengerDoorSt 1 "Open" 0 "Close" ;
VAL_ 672 BCM1_DriverDoorLockSt 3 "Reserved" 2 "Reserved" 1 "Unlock" 0 "Lock" ;
VAL_ 672 BCM1_DriverDoorSt 1 "Open" 0 "Close" ;
VAL_ 672 BCM1_SteeringLightSt 3 "Reserved" 2 "Right On" 1 "Left On" 0 "Off" ;
VAL_ 672 BCM1_HazardLightSt 3 "Reserved" 2 "Reserved" 1 "On" 0 "Off" ;
